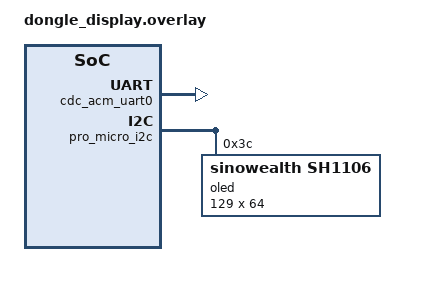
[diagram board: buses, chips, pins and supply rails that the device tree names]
/*
 * Copyright (c) 2024 The ZMK Contributors
 *
 * SPDX-License-Identifier: MIT
 */

/ {
    chosen {
        zephyr,display = &oled;
        zephyr,console = &cdc_acm_uart0;
        zephyr,shell-uart = &cdc_acm_uart0;
    };
};

&usbd {
    cdc_acm_uart0: cdc_acm_uart0 {
        compatible = "zephyr,cdc-acm-uart";
        status = "okay";
    };
};

&pro_micro_i2c {
    status = "okay";
    oled: sh1106@3c {
        compatible = "sinowealth,sh1106";
        reg = <0x3c>;
        width = <129>;
        height = <64>;
        segment-offset = <1>;
        page-offset = <0>;
        display-offset = <0>;
        multiplex-ratio = <63>;
        segment-remap;
        com-invdir;
        inversion-on;
        prechargep = <0x22>;
    };
};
